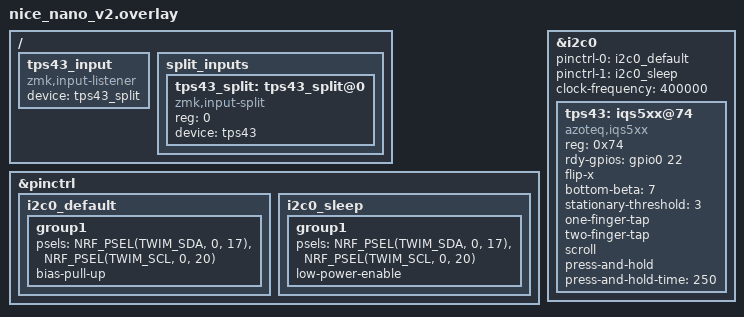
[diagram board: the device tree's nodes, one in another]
/ {
    /* O listener original aponta para o túnel do rádio (tps43_split) */
    tps43_input: tps43_input {
        compatible = "zmk,input-listener";
        device = <&tps43_split>; 
    };

    /* Define o túnel de comunicação entre os lados */
    split_inputs {
        #address-cells = <1>;
        #size-cells = <0>;

        tps43_split: tps43_split@0 {
            compatible = "zmk,input-split";
            reg = <0>;
            /* O dispositivo real que está no lado direito */
            device = <&tps43>; 
        };
    };
};

&pinctrl {
    i2c0_default: i2c0_default {
        group1 {
            psels = <NRF_PSEL(TWIM_SDA, 0, 17)>,
                    <NRF_PSEL(TWIM_SCL, 0, 20)>;
            bias-pull-up;
        };
    };

    i2c0_sleep: i2c0_sleep {
        group1 {
            psels = <NRF_PSEL(TWIM_SDA, 0, 17)>,
                    <NRF_PSEL(TWIM_SCL, 0, 20)>;
            low-power-enable;
        };
    };
};

&i2c0 {
    status = "okay";
    pinctrl-0 = <&i2c0_default>;
    pinctrl-1 = <&i2c0_sleep>;
    pinctrl-names = "default", "sleep";
    clock-frequency = <400000>;

    tps43: iqs5xx@74 {
        compatible = "azoteq,iqs5xx";
        reg = <0x74>;
        status = "okay";
        rdy-gpios = <&gpio0 22 (GPIO_ACTIVE_HIGH | GPIO_PULL_DOWN)>;

        flip-x; 
        
        /* --- CALIBRAÇÃO ANTI-TREMIDO (ESTILO APPLE) --- */
        bottom-beta = <7>;             /* Filtro IIR pesado para suavizar o rastro do ponteiro */
        stationary-threshold = <3>;    /* Estabiliza o clique e ignora ruído do dedo parado */

        /* GESTOS NATIVOS SUPORTADOS */
        one-finger-tap;
        two-finger-tap;
        scroll;
        press-and-hold;
        press-and-hold-time = <250>; 
    };
};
